# CY8C5888LTI_LP097 register map
File version: 0.1
Registers are 8-bit, read-write, no defined reset value unless marked. A register's access mark holds for its fields unless they carry their own. Offsets are from the block's base; [hi:lo] are bit positions; {n}, {i} and the like mark numbered series; 'fields as' and 'values as' point back to an identical list.

## ADC_DelSig_1
Base 0x00000000
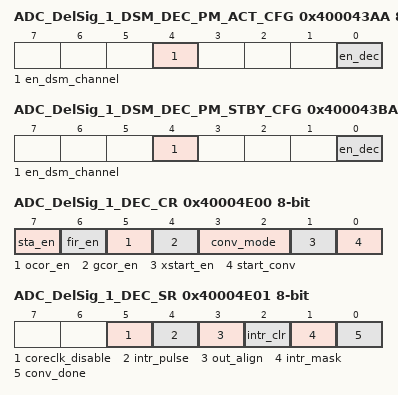
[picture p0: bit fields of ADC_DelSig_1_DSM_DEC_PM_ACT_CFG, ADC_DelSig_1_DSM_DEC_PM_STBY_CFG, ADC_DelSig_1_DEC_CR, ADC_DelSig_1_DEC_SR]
0x400043AA ADC_DelSig_1_DSM_DEC_PM_ACT_CFG — Decimator Active mode Power Register
  [4] en_dsm_channel — Enable delta-sigma modulator ADC channel. Note: set the appropriate enables in the analog interface prior to setting this global enable for the channel.
    0=Disable_DSM_Channel (Disable power to DSM channel.); 1=Enable_DSM_Channel (Enable power to DSM channel.)
  [0] en_dec — Enable decimator(s). Populated subsystems are counted from the LSB.
    0=DIS_DEC (Disable power to Decimator.); 1=EN_DEC (Enable power to Decimator.)
0x400043BA ADC_DelSig_1_DSM_DEC_PM_STBY_CFG — Decimator Alternate Active mode Power Register
  [4] en_dsm_channel — Enable delta-sigma modulator ADC channel. Note: set the appropriate enables in the analog interface prior to setting this global enable for the channel.
    0=Disable_DSM_Channel (Disable power to DSM channel.); 1=Enable_DSM_Channel (Enable power to DSM channel during Standby power mode.)
  [0] en_dec — Enable decimator(s). Populated subsystems are counted from the LSB.
    0=DIS_DEC (Disable power to Decimator.); 1=EN_DEC (Enable power to Decimator during Standby power mode.)
0x40004E00 ADC_DelSig_1_DEC_CR — Decimator Control Register
  [7] sta_en — Controls saturation logic in the Post Processing filter. When enabled, the resulting outputs of the Post Processing filter are held to the most positive or negative values, rather then wrapping around. Conversion results are unpredictable if this bit is changed while the Post Processing filter is running. This bit is ignored if FIR_EN, OCOR_EN and GCOR_EN are all 0.
    0=SAT_DIS (No saturation control.); 1=SAT_EN (Saturation Control Enabled.)
  [6] fir_en — Controls whether or not Post Processing filter implements a FIR filter. If this bit is set it enables the Post Processing filter. Conversion results are unpredictable if this bit is changed while the filter is running. The decimation period of this filter is controlled by the DR2 bits in register DR2 and DR2H.
    0=FIR_DIS (FIR filter function Disabled.); 1=FIR_EN (FIR filter function is on.)
  [5] ocor_en — This bit controls the offset correction feature of the Post Processing filter. If this bit is set it enables the Post Processing filter. The offset value is programmed in the OCOR bits of registers OCOR, OCORM and OCORH. Conversion results are unpredictable if this bit is changed while the filter is running.
    0=OCOR_DIS (No offset correction.); 1=OCOR_EN (Offset correction enabled.)
  [4] gcor_en — This bit controls the gain correction feature of the Post Processing filter. If this bit is set it enables the Post Processing filter. The gain coefficient is programmed in the GCOR bits of registers GCOR and GCORH. Which bits in this 16-bit field that are valid is set in GVAL. Conversion results are unpredictable if this bit is changed while the filter is running. When this feature is enabled, the DR1 register field must be set to a value higher than 32 (worst case) for proper operation.
    0=GCOR_DIS (Default: no gain correction.); 1=GCOR_EN (Gain correction enabled.)
  [3:2] conv_mode — The value in these two bits controls the sampling mode the Decimator runs in.
    0=SINGLE_SAMPLE (Single Sample Mode.); 1=FAST_FILTER (Fast Filter Mode.); 2=CONTINUOUS (Continuous Mode.); 3=FAST_FIR
  [1] xstart_en — Controls whether DSI signal ext_start is active. If XSTART_EN is high, it allows the ext_start input to start a conversion just as START_CONV does. Regardless of the state of this bit, writing to START_CONV will start a conversion.
    0=XSTART_DIS (Default: DSI signal ext_start is disabled.); 1=XSTART_EN (Enable the DSI input signal ext_start to start a conversion.)
  [0] start_conv — A write of 1 to this bit starts a conversion (regardless of the state of XSTART_EN) according to the CONV_MODE set in bits 2, 3. If read, a 1 indicates the filter is running when not in Single Sample mode. If a 0 is read the block is in the standby state when not in Single Sample mode. When in Single Sample more this bit is cleared shortly after it is written and does not reflect the running state of the Decimator.
    0=DEC_STOP (Kill current conversion (if running) and enter Standby state (SW reset).); 1=DEC_START (Initiate a conversion.)
0x40004E01 ADC_DelSig_1_DEC_SR — Decimator Status Register
  [5] coreclk_disable — This bit when set high disables (gates off) the clock to the entire core of the block (adc_clk). This includes all FFs except those used for the AHB interface and CSRs. When disabled (set high) the AHB interface to the CSR is still fully functional. This bit is ANDed with the primary input signal cic_clk_en to control the clock gate. cic_clk_en must be high and CoreCLK_Disable must be low for the clock to run.
    0=CORECLK_DISABLE_LOW (Core Clock is Enabled.); 1=CORECLK_DISABLE_HIGH (Core Clock is Disabled.)
  [4] intr_pulse — This read/write bit selects if cic_intr is pulse or level sensed. If level, a sample completion sets cic_intr high where it remains until bit 2 is written, a soft-reset if performed or if OUTSAMP/M/H is read. If pulse, a single cycle (pclk) strobe is generated on cic_intr to be used as an edge sensed interrupt or a DMAREQ. Regardless of which is selected, the interrupt output is still subject to masking by bit 1.
    0=INTR_LEVEL (Selects a level interrupt on cic_intr.); 1=INTR_PULSE (Selects a pulse interrupt on cic_intr.)
  [3] out_align — This bit when set high causes a read of OUTSAMP to produce the contents of OUTSAMPM and OUTSAMPM to produce the contents of OUTSAMPH. Effectively, this is an 8-bit right shift of the result. Note that the setting of this bit does not alter the content of the OUTSAMP registers. Setting this bit simply realigns the byte lanes when the register is read. If this bit is set low, the OUTSAMP registers are read normally.
    0=OUT_ALIGN_LOW (No affect on SAMP Registers.); 1=OUT_ALIGN_HIGH (Shifts SAMP registers right by 8-bits.)
  [2] intr_clr wo — INTR_CLR is a write-only bit that clears bit0 and cic_intr. A read always produces a 0.
    0=INTR_NOP (No affect.); 1=INTR_CLEAR (Clears CONV_DONE and the interrupt on cic_intr (if enabled).)
  [1] intr_mask — INTR_MASK is a RD/WR bit that controls the generation of the conversion completion interrupt. A read produces that last value written to this bit. This bit functions as a mask regardless of the value of bit 4 (INTR PULSE).
    0=INTR_ENABLED (Allows CONV_DONE to generate an interrupt.); 1=INTR_MASKED (Masks the interrupt generation on cic_intr.)
  [0] conv_done ro — CONV_DONE is a read-only bit indicating that the most recently started conversion has completed if it has been cleared since the last sample read. This same bit is the interrupt signal cic_intr when bit 4 is low, if not masked by bit 1. This bit is intended to provide a polling mechanism should this be preferred to receiving interrupts. It is cleared by writing a 1 to bit 2, a soft-reset or a read of register OUTSAMP, OUTSAMPM or OUTSAMPH (regardless of Coherency settings).
    0=CONV_NOTCOMP (Most recently started conversion completed.); 1=CONV_COMP (Conversion not completed since last clear.)
0x40004E02 ADC_DelSig_1_DEC_SHIFT1 — Decimator Shift Register
  [4:0] shift1 — Value for left shift amount of modulator input data. 0 = no shift, 1 = left shift by 1 bit, .... up to the max supported 31.
0x40004E03 ADC_DelSig_1_DEC_SHIFT2 — Decimator Shift Register
  [3:0] shift2 — Value for the amount of right shift for the output of the CIC filter prior to entering the Post Processor. Functional values range from 0 to 15, 0 = no shift.
0x40004E04 ADC_DelSig_1_DEC_DR2 — Decimator Decimation Rate (2) Register
  [7:0] dr2_low — FIR Filter decimation ratio bits [7:0] (of [9:0]).
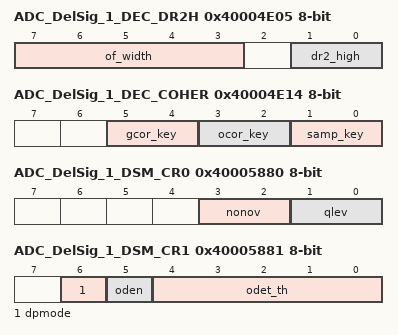
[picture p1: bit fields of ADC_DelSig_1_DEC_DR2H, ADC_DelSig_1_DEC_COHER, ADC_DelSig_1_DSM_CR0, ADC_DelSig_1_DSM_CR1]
0x40004E05 ADC_DelSig_1_DEC_DR2H — Decimator Decimation Rate and Overflow Correction Register
  [7:3] of_width — Occupying the top 5 bits of this register is the Overflow Correction Bit-Width field (it is unrelated to the DR2). This field both enables and sets the bit width of the Overflow Correction logic in the CIC core.
  [1:0] dr2_high — FIR Filter decimation ratio bits [9:8] (of [9:0]). See description in DR2 register.
0x40004E06 ADC_DelSig_1_DEC_DR1 — Decimator Decimation Rate (1) Register
  [7:0] dr1 — CIC Filter decimation rate.
0x40004E08 ADC_DelSig_1_DEC_OCOR — Decimator Offset Correction Coefficient (Low Byte) Register
  [7:0] ocor_low — Offset correction coefficient bits [7:0] (of [23:0]).
0x40004E09 ADC_DelSig_1_DEC_OCORM — Decimator Offset Correction Coefficient (Middle Byte) Register
  [7:0] ocor_mid — Offset correction coefficient bits [15:8] (of [23:0]).
0x40004E0A ADC_DelSig_1_DEC_OCORH — Decimator Offset Correction Coefficient (High Byte) Register
  [7:0] ocor_high — Offset correction coefficient bits [23:16] (of [23:0]).
0x40004E0C ADC_DelSig_1_DEC_GCOR — Decimator Gain Correction Coefficient (Low Byte) Register
  [7:0] gcor_low — Gain correction coefficient bits [7:0] (of [15:0]).
0x40004E0D ADC_DelSig_1_DEC_GCORH — Decimator Gain Correction Coefficient (High Byte) Register
  [7:0] gcor_high — Gain correction coefficient bits [15:8] (of [15:0]).
0x40004E0E ADC_DelSig_1_DEC_GVAL — Decimator Gain Correction Size Register
  [3:0] gval — Number of valid bits minus one in Gain Coefficient registers GCORH and GCOR.
0x40004E10 ADC_DelSig_1_DEC_OUTSAMP — Decimator Output Data Sample (Low Byte) Register
  [7:0] samp_low ro — Low order byte of the filter conversion result, bits [7:0] (of [23:0]) --- Or if the out_align bit is set it contains bits [15:8] (of [23:0]).
0x40004E11 ADC_DelSig_1_DEC_OUTSAMPM — Decimator Output Data Sample (Middle Byte) Register
  [7:0] samp_mid ro — Middle order byte of the filter conversion result, bits [15:8] (of [23:0]) --- Or if the out_align bit is set it contains bits [23:16] (of [23:0]).
0x40004E12 ADC_DelSig_1_DEC_OUTSAMPH — Decimator Output Data Sample (High Byte) Register
  [7:0] samp_high ro — High order byte of the filter conversion result, bits [23:16] (of [23:0]).
0x40004E14 ADC_DelSig_1_DEC_COHER — Decimator Coherency Register
  [5:4] gcor_key — Sets the Key Coherency Byte of the GCOR/GCORH/GVAL field.
    0=GCOR_KEY_OFF (Gain Coefficient Coherency checking off.); 1=GCOR_KEY_LOW (Key Byte is low byte (GCOR).); 2=GCOR_KEY_MID (Key Byte is middle byte (GCORH).); 3=GCOR_KEY_HIGH (Key Byte is high byte (GVAL).)
  [3:2] ocor_key — Sets the Key Coherency Byte of the OCOR/OCORM/OCORH field.
    0=OCOR_KEY_OFF (Offset Coefficient Coherency checking off.); 1=OCOR_KEY_LOW (Key Byte is low byte (OCOR).); 2=OCOR_KEY_MID (Key Byte is middle byte (OCORM).); 3=OCOR_KEY_HIGH (Key Byte is high byte (OCORH).)
  [1:0] samp_key — Sets the Key Coherency Byte of the OUTSAMP/OUTSAMPM/OUTSAMPH field.
    0=SAMP_KEY_OFF (Output Sample Coherency checking off.); 1=SAMP_KEY_LOW (Key Byte is low byte (OUTSAMP).); 2=SAMP_KEY_MID (Key Byte is middle byte (OUTSAMPM).); 3=SAMP_KEY_HIGH (Key Byte is high byte (OUTSAMPH).)
0x40005880 ADC_DelSig_1_DSM_CR0 — Delta Sigma Modulator Control Register 0
  [3:2] nonov — Non overlap delay of clock phases.
    0=NONOV_LOW (low (1.57ns, typ).); 1=NONOV_MEDIUM (medium (3.54ns, typ).); 2=NONOV_HIGH (high (6.47ns, typ).); 3=NONOV_VERYHIGH (very high (9.91ns, typ).)
  [1:0] qlev — Quantization Level choice for modulator.
    0=2 level quantization; 1=3 level quantization; 2=9 level quantization; 3=QLEV_9_ALSO (9 level quantization.)
0x40005881 ADC_DelSig_1_DSM_CR1 — Delta Sigma Modulator Control Register 1
  [6] dpmode — Datapath mode.
    0=DPMODE_NORMAL (normal.); 1=DPMODE_LOWOFFSET (low offset.)
  [5] oden — Overload detect scheme enable.
  [4:0] odet_th — Overload detection threshold. If the number of continuous 1s or 0s coming out of quantizer exceeds this number overload detection flag is set.
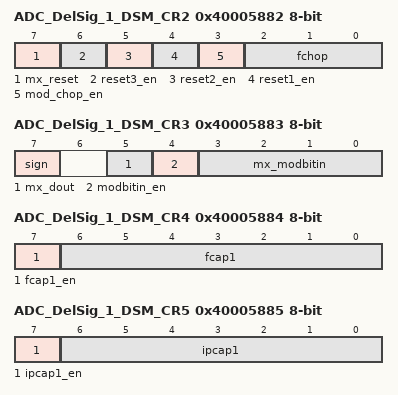
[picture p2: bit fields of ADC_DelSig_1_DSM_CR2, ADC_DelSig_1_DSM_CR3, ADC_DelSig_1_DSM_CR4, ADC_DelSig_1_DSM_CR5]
0x40005882 ADC_DelSig_1_DSM_CR2 — Delta Sigma Modulator Control Register 2
  [7] mx_reset — select DSM reset source.
    0=MXSELRESET_0 (Select Decimator for reset source.); 1=MXSELRESET_1 (Select UDB for reset source.)
  [6] reset3_en — allow third stage integrating capacitance to be reset.
    0=RESET3_EN_DISABLE (third stage integrating capacitance cannot be reset (use only for debug purposes).); 1=RESET3_EN_ENABLE (third stage integrating capacitance can be reset.)
  [5] reset2_en — allow second stage integrating capacitance to be reset.
    0=RESET2_EN_DISABLE (second stage integrating capacitance cannot be reset (use when in overload, to allow for second order operation, assuming the reset1_en bit is also cleared.); 1=RESET2_EN_ENABLE (second stage integrating capacitance can be reset.)
  [4] reset1_en — Allow first stage integrating capacitance to be reset.
    0=RESET1_EN_DISABLE (First stage integrating capacitance cannot be reset (use when in overload, to allow for first order operation).); 1=RESET1_EN_ENABLE (First stage integrating capacitance can be reset.)
  [3] mod_chop_en — Enable Modulator Chopping.
    0=MOD_CHOP_DIS (Disable modulator chopping.); 1=MOD_CHOP_EN (Enable modulator chopping.)
  [2:0] fchop — Chopping Frequency Selection. The Fclock is samply frequency clock.
    0=FCHOP_DIV2 (Fclock/2.); 1=FCHOP_DIV4 (Fclock/4.); 2=FCHOP_DIV8 (Fclock/8.); 3=FCHOP_DIV16 (Fclock/16.); 4=FCHOP_DIV32 (Fclock/32.); 5=FCHOP_DIV64 (Fclock/64.); 6=FCHOP_DIV128 (Fclock/128.); 7=FCHOP_DIV256 (Fclock/256.)
0x40005883 ADC_DelSig_1_DSM_CR3 — Delta Sigma Modulator Control Register 3
  [7] sign — Invert sign of input.
    0=SIGN_NONINVERT (keep original polarity for the input.); 1=SIGN_INVERT (Invert sign of input (use when trying to chop once and then average the offset value out).)
  [5] mx_dout — Select DSM dout routed to UDB.
    0=MX_DOUT_8BIT (Select reg OUT0=dout[7:0] (synced; w/o post processing).); 1=MX_DOUT_2SCOMP (Select reg OUT1={2'b0,ovdcause,ovdflag,dout2scomp} (synced; overload cause, overload flag, dout 2s complement.)
  [4] modbitin_en — modbitin enable.
    0=MODBITIN_EN_DISABLE (Do not allow modbit input to be mixed with modulator input.); 1=MODBITIN_EN_ENABLE (Allow modbit input to be mixed with modulator input.)
  [3:0] mx_modbitin — Select modbitin input.
    {v}=MX_MODBITIN_LUT{v} (lut{v}_out.) (v=0..3); {v}=MX_MODBITIN_LUT{v} (lut{v}_out (doesn't exist on Leopard, tied to 0).) (v=4..7); 8=MX_MODBITIN_UDB (UDB.); 9=MX_MODBITIN_CONST1 (constant 1.); 10=MX_MODBITIN_CONST0 (constant 0.); {v}=MX_MODBITIN_{0x0+v}_RSVD (Reserved.) (v=11..15)
0x40005884 ADC_DelSig_1_DSM_CR4 — Delta Sigma Modulator Control Register 4
  [7] fcap1_en — Enable/Disable Capacitance path meant for DFT (Design for Testability) of the first integrator's integrating capacitance path.
    0=FCAP1_EN_DISABLE (Disable the DFT 100fF capacitance path.); 1=FCAP1_EN_ENABLE (Enable the DFT 100fF capacitance path.)
  [6:0] fcap1 — binary weighted first stage integrating capacitance.
    0=FCAP1_MIN (0 fF.); 127=FCHOP_MAX (Max Value = 12.7 pF.); 1=FCAP1_BIT0 (fcap[0] set -> +100 fF.); 2=FCAP1_BIT1 (fcap[1] set -> +200 fF.); 4=FCAP1_BIT2 (fcap[2] set -> +400 fF.); 8=FCAP1_BIT3 (fcap[3] set -> +800 fF.); 16=FCAP1_BIT4 (fcap[4] set -> +1600 fF.); 32=FCAP1_BIT5 (fcap[5] set -> +3200 fF.); 64=FCAP1_BIT6 (fcap[6] set -> +6400 fF.)
0x40005885 ADC_DelSig_1_DSM_CR5 — Delta Sigma Modulator Control Register 5
  [7] ipcap1_en — Enable/Disable Capacitance path meant for DFT (Design for Testability) of the first integrator's input sampling path.
    0=IPCAP1_EN_DISABLE (Disable the DFT 100fF capacitance path.); 1=IPCAP1_EN_ENABLE (Enable the DFT 100fF capacitance path.)
  [6:0] ipcap1 — Binary weighted first stage integrating capacitance.
    0=IPCAP1_MIN (0 fF.); 127=IPCHOP_MAX (Max Value = 12.7 pF.); 1=IPCAP1_BIT0 (ipcap[0] set -> +100 fF.); 2=IPCAP1_BIT1 (ipcap[1] set -> +200 fF.); 4=IPCAP1_BIT2 (ipcap[2] set -> +400 fF.); 8=IPCAP1_BIT3 (ipcap[3] set -> +800 fF.); 16=IPCAP1_BIT4 (ipcap[4] set -> +1600 fF.); 32=IPCAP1_BIT5 (ipcap[5] set -> +3200 fF.); 64=IPCAP1_BIT6 (ipcap[6] set -> +6400 fF.)
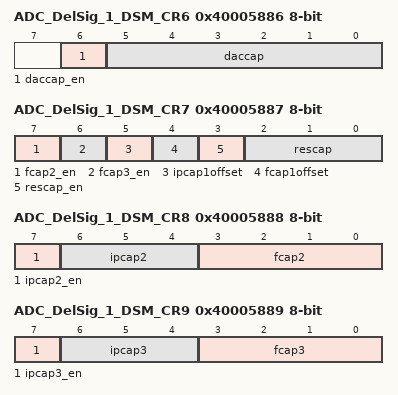
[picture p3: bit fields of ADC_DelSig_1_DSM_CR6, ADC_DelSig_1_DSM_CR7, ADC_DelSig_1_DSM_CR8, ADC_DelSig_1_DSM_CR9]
0x40005886 ADC_DelSig_1_DSM_CR6 — Delta Sigma Modulator Control Register 6
  [6] daccap_en — Enable/Disable Capacitance path meant for DFT (Design for Testability) of the DAC Reference sampling path.
    0=DACCAP_EN_DISABLE (Disable the DFT 12fF capacitance path.); 1=DACCAP_EN_ENABLE (Enable the DFT 12fF capacitance path.)
  [5:0] daccap — Binary weighted first stage DAC capacitance.
    1=DACCAP_BIT0 (daccap[0] set -> add 12*8= +96 fF.); 2=DACCAP_BIT1 (daccap[1] set -> add 24*8= +192 fF.); 4=DACCAP_BIT2 (daccap[2] set -> add 50*8= +400 fF.); 8=DACCAP_BIT3 (daccap[3] set -> add 100*8= +800 fF.); 16=DACCAP_BIT4 (daccap[4] set -> add 200*8= +1600 fF.); 32=DACCAP_BIT5 (daccap[5] set -> add 400*8= +3200 fF.)
0x40005887 ADC_DelSig_1_DSM_CR7 — Delta Sigma Modulator Control Register 7
  [7] fcap2_en — Enable/Disable additional 50fF capacitance path in the second integrators integrating capacitance path.
    0=FCAP2_EN_DISABLE (Disable the additional 50fF capacitance path.); 1=FCAP2_EN_ENABLE (Enable the additional 50fF capacitance path.)
  [6] fcap3_en — Enable/Disable additional capacitance path in the third integrator's integrating capacitance path.
    0=FCAP3_EN_DISABLE (Disable the additional 100fF capacitance path.); 1=FCAP3_EN_ENABLE (Enable the additional 100fF capacitance path.)
  [5] ipcap1offset — Offset capacitance for the input sampling capacitance in the first stage integrator.
    0=Don't add offset capacitance; 1=Add offset capacitance of 4.8 pF
  [4] fcap1offset — Offset Capacitance for the integrating capacitance in the first stage integrator.
    0=Don't add offset capacitance; 1=Add offset capacitance of 3.4 pF
  [3] rescap_en — Reserved. The resonator loop feature has been disabled in the design; programming these bits does not produce any change in the ADC outcome.
  [2:0] rescap — Reserved. The resonator loop feature has been disabled in the design; programming these bits does not produce any change in the ADC outcome.
0x40005888 ADC_DelSig_1_DSM_CR8 — Delta Sigma Modulator Control Register 8
  [7] ipcap2_en — Enable/Disable additional 50fF capacitance path in the second integrator's input sampling path.
    0=IPCAP2_EN_DISABLE (Disable the additional 50fF capacitance path.); 1=IPCAP2_EN_ENABLE (Enable the additional 50fF capacitance path.)
  [6:4] ipcap2 — The second integrator's input sampling capacitance (0-350fF, 50fF step).
    0=IPCAP2_0FEMPTO (0fF.); 1=IPCAP2_50FEMPTO (50fF.); 2=IPCAP2_100FEMPTO (100fF.); 3=IPCAP2_150FEMPTO (150fF.); 4=IPCAP2_200FEMPTO (200fF.); 5=IPCAP2_250FEMPTO (250fF.); 6=IPCAP2_300FEMPTO (300fF.); 7=IPCAP2_350FEMPTO (350fF.)
  [3:0] fcap2 — The second stage integrating capacitance (0-750fF, 50fF step).
    0=FCAP2_0FEMPTO (0fF.); 1=FCAP2_50FEMPTO (50fF.); 2=FCAP2_100FEMPTO (100fF.); 3=FCAP2_150FEMPTO (150fF.); 4=FCAP2_200FEMPTO (200fF.); 5=FCAP2_250FEMPTO (250fF.); 6=FCAP2_300FEMPTO (300fF.); 7=FCAP2_350FEMPTO (350fF.); 8=FCAP2_400FEMPTO (400fF.); 9=FCAP2_450FEMPTO (450fF.); 10=FCAP2_500FEMPTO (500fF.); 11=FCAP2_550FEMPTO (550fF.); 12=FCAP2_600FEMPTO (600fF.); 13=FCAP2_650FEMPTO (650fF.); 14=FCAP2_700FEMPTO (700fF.); 15=FCAP2_750FEMPTO (750fF.)
0x40005889 ADC_DelSig_1_DSM_CR9 — Delta Sigma Modulator Control Register 9
  [7] ipcap3_en — Enable/Disable additional 50fF capacitance path in the second integrator's input sampling path.
    0=IPCAP3_EN_DISABLE (Disable the additional 50fF capacitance path.); 1=IPCAP3_EN_ENABLE (Enable the additional 50fF capacitance path.)
  [6:4] ipcap3 — The third integrator's input sampling capacitance (0-350fF in 50fF step).
    0=IPCAP3_0FEMPTO (0fF.); 1=IPCAP3_50FEMPTO (50fF.); 2=IPCAP3_100FEMPTO (100fF.); 3=IPCAP3_150FEMPTO (150fF.); 4=IPCAP3_200FEMPTO (200fF.); 5=IPCAP3_250FEMPTO (250fF.); 6=IPCAP3_300FEMPTO (300fF.); 7=IPCAP3_350FEMPTO (350fF.)
  [3:0] fcap3 — The third stage integrating capacitance (0-1500fF, 100fF step).
    0=FCAP3_0FEMPTO (0fF.); 1=FCAP3_100FEMPTO (100fF.); 2=FCAP3_200FEMPTO (200fF.); 3=FCAP3_300FEMPTO (300fF.); 4=FCAP3_400FEMPTO (400fF.); 5=FCAP3_500FEMPTO (500fF.); 6=FCAP3_600FEMPTO (600fF.); 7=FCAP3_700FEMPTO (700fF.); 8=FCAP3_800FEMPTO (800fF.); 9=FCAP3_900FEMPTO (900fF.); 10=FCAP3_1000FEMPTO (1000fF.); 11=FCAP3_1100FEMPTO (1100fF.); 12=FCAP3_1200FEMPTO (1200fF.); 13=FCAP3_1300FEMPTO (1300fF.); 14=FCAP3_1400FEMPTO (1400fF.); 15=FCAP3_1500FEMPTO (1500fF.)
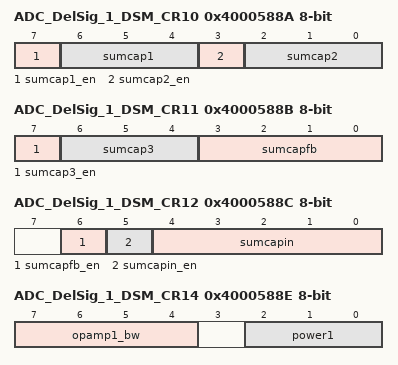
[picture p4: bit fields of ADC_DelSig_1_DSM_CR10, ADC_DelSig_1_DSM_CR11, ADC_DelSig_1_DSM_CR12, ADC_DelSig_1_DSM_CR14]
0x4000588A ADC_DelSig_1_DSM_CR10 — Delta Sigma Modulator Control Register 10
  [7] sumcap1_en — Enabling/Disabling the the additional 50fF capacitance path that lies between first integrator output and summer input (feed-forward) path.
    0=SUMCAP1_EN_DISABLE (Disable the additional 50fF capacitance path.); 1=SUMCAP1_EN_ENABLE (Enable the additional 50fF capacitance path.)
  [6:4] sumcap1 — The summer capacitance that lies on the feed-forward path from the first integrator output (0fF to 350fF in 50fF step).
    0=SUMCAP1_0FEMPTO (0fF.); 1=SUMCAP1_50FEMPTO (50fF.); 2=SUMCAP1_100FEMPTO (100fF.); 3=SUMCAP1_150FEMPTO (150fF.); 4=SUMCAP1_200FEMPTO (200fF.); 5=SUMCAP1_250FEMPTO (250fF.); 6=SUMCAP1_300FEMPTO (300fF.); 7=SUMCAP1_350FEMPTO (350fF.)
  [3] sumcap2_en — Enabling/Disabling the additional 50fF capacitance path that lies between the second integrator output and summer input (feed-forward) path.
    0=SUMCAP2_EN_DISABLE (Disable the additional 50fF capacitance path.); 1=SUMCAP2_EN_ENABLE (Enable the additional 50fF capacitance path.)
  [2:0] sumcap2 — The summer capacitance that lies on the feed-forward path from the second integrator output (0fF to 350fF in 50fF step.
    0=SUMCAP2_0FEMPTO (0fF.); 1=SUMCAP2_50FEMPTO (50fF.); 2=SUMCAP2_100FEMPTO (100fF.); 3=SUMCAP2_150FEMPTO (150fF.); 4=SUMCAP2_200FEMPTO (200fF.); 5=SUMCAP2_250FEMPTO (250fF.); 6=SUMCAP2_300FEMPTO (300fF.); 7=SUMCAP2_350FEMPTO (350fF.)
0x4000588B ADC_DelSig_1_DSM_CR11 — Delta Sigma Modulator Control Register 11
  [7] sumcap3_en — Enabling/Disabling the additional 50fF path that lies between the third integrator output and summer input (feed-forward) path.
    0=SUMCAP3_EN_DISABLE (Disable the additional 50fF capacitance path.); 1=SUMCAP3_EN_ENABLE (Enable the additional 50fF capacitance path.)
  [6:4] sumcap3 — The summer capacitance that lies on the feed-forward path from the third integrator output (0fF to 350fF in 50fF step.
    0=SUMCAP3_0FEMPTO (0fF.); 1=SUMCAP3_50FEMPTO (50fF.); 2=SUMCAP3_100FEMPTO (100fF.); 3=SUMCAP3_150FEMPTO (150fF.); 4=SUMCAP3_200FEMPTO (200fF.); 5=SUMCAP3_250FEMPTO (250fF.); 6=SUMCAP3_300FEMPTO (300fF.); 7=SUMCAP3_350FEMPTO (350fF.)
  [3:0] sumcapfb — The summer feedback capacitance (0fF to 750F in 50fF step).
    0=SUMCAPFB_0FEMPTO (0fF.); 1=SUMCAPFB_50FEMPTO (50fF.); 2=SUMCAPFB_100FEMPTO (100fF.); 3=SUMCAPFB_150FEMPTO (150fF.); 4=SUMCAPFB_200FEMPTO (200fF.); 5=SUMCAPFB_250FEMPTO (250fF.); 6=SUMCAPFB_300FEMPTO (300fF.); 7=SUMCAPFB_350FEMPTO (350fF.); 8=SUMCAPFB_400FEMPTO (400fF.); 9=SUMCAPFB_450FEMPTO (450fF.); 10=SUMCAPFB_500FEMPTO (500fF.); 11=SUMCAPFB_550FEMPTO (550fF.); 12=SUMCAPFB_600FEMPTO (600fF.); 13=SUMCAPFB_650FEMPTO (650fF.); 14=SUMCAPFB_700FEMPTO (700fF.); 15=SUMCAPFB_750FEMPTO (750fF.)
0x4000588C ADC_DelSig_1_DSM_CR12 — Delta Sigma Modulator Control Register 12
  [6] sumcapfb_en — Enabling/Disabling the DFT path that lies on the feedback path of the active summer.
    0=SUMCAPFB_EN_DISABLE (Disable the DFT 50fF capacitance path.); 1=SUMCAPFB_EN_ENABLE (Enable the DFT 50fF capacitance path.)
  [5] sumcapin_en — Enabling/Disabling the DFT path that lies between input of the sigma delta modulator and the summer input..
    0=SUMCAPIN_EN_DISABLE (Disable the DFT 50fF capacitance path.); 1=SUMCAPIN_EN_ENABLE (Enable the DFT 50fF capacitance path.)
  [4:0] sumcapin — The summer capacitance that lies on the path where the input signal is summed (50fF to 1.6pF in 50fF step).
    0=SUMCAPIN_0FEMPTO (0fF.); 1=SUMCAPIN_50FEMPTO (50fF.); 2=SUMCAPIN_100FEMPTO (100fF.); 3=SUMCAPIN_150FEMPTO (150fF.); 4=SUMCAPIN_200FEMPTO (200fF.); 5=SUMCAPIN_250FEMPTO (250fF.); 6=SUMCAPIN_300FEMPTO (300fF.); 7=SUMCAPIN_350FEMPTO (350fF.); 8=SUMCAPIN_400FEMPTO (400fF.); 9=SUMCAPIN_450FEMPTO (450fF.); 10=SUMCAPIN_500FEMPTO (500fF.); 11=SUMCAPIN_550FEMPTO (550fF.); 12=SUMCAPIN_600FEMPTO (600fF.); 13=SUMCAPIN_650FEMPTO (650fF.); 14=SUMCAPIN_700FEMPTO (700fF.); 15=SUMCAPIN_750FEMPTO (750fF.); 16=SUMCAPIN_800FEMPTO (800fF.); 17=SUMCAPIN_850FEMPTO (850fF.); 18=SUMCAPIN_900FEMPTO (900fF.); 19=SUMCAPIN_950FEMPTO (950fF.); 20=SUMCAPIN_1000FEMPTO (1000fF.); 21=SUMCAPIN_1050FEMPTO (1050fF.); 22=SUMCAPIN_1100FEMPTO (1100fF.); 23=SUMCAPIN_1150FEMPTO (1150fF.); 24=SUMCAPIN_1200FEMPTO (1200fF.); 25=SUMCAPIN_1250FEMPTO (1250fF.); 26=SUMCAPIN_1300FEMPTO (1300fF.); 27=SUMCAPIN_1350FEMPTO (1350fF.); 28=SUMCAPIN_1400FEMPTO (1400fF.); 29=SUMCAPIN_1450FEMPTO (1450fF.); 30=SUMCAPIN_1500FEMPTO (1500fF.); 31=SUMCAPIN_1550FEMPTO (1550fF.)
0x4000588D ADC_DelSig_1_DSM_CR13 — Delta Sigma Modulator Control Register 13
0x4000588E ADC_DelSig_1_DSM_CR14 — Delta Sigma Modulator Control Register 14
  [7:4] opamp1_bw — First Stage Opamp Bandwidth Control (Risk Mitigation not for User control). Table gives value for Modulator input bw[3:0].
    0=(default); 1=(used with 1.5X power); 3=(used with 2X power); 7=(used with 2.5X power); 8=(higher BW, 1.25X power); 9=(lower noise)
  [2:0] power1 — First Stage Opamp Power level control.
    0=Low (44uA); 1=Medium (123uA); 2=High (492uA); 3=1.5X (750uA); 4=2X (1mA); 5=C/2 @ 3MSPS (277uA); 6=C/4 @ 3MSPS (185uA); 7=2.5X (1.5mA)
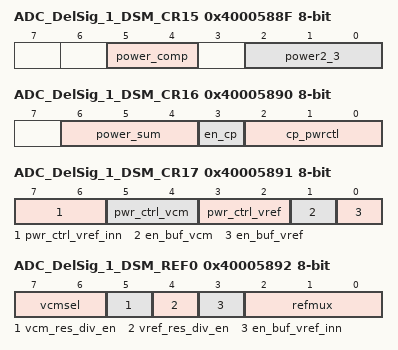
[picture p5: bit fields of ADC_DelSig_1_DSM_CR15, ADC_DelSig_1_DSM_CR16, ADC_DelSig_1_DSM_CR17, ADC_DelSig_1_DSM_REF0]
0x4000588F ADC_DelSig_1_DSM_CR15 — Delta Sigma Modulator Control Register 15
  [5:4] power_comp — The power control for the quantizer block.
    0=POWER_COMP_VERYLOW (very low (2.2uA)); 1=POWER_COMP_NORMAL (Normal (8.6uA)); 2=POWER_COMP_6MHZ (6MHz (17uA)); 3=POWER_COMP_12MHZ (12MHz (35uA))
  [2:0] power2_3 — The power control for the second and third integrator stages.
    0=POWER2_3_LOW (LOW (4uA)); 1=POWER2_3_MEDIUM (MEDIUM (17uA)); 2=POWER2_3_HIGH (HIGH (68uA)); 3=POWER2_3_1P5X (1.5X (100uA)); 4=POWER2_3_2X (2X (135uA)); 5=POWER2_3_HIGH_5 (HIGH (68uA)); 6=POWER2_3_HIGH_6 (HIGH (68uA)); 7=POWER2_3_HIGH_7 (HIGH (68uA))
0x40005890 ADC_DelSig_1_DSM_CR16 — Delta Sigma Modulator Control Register 16
  [6:4] power_sum — The power control for the summer block.
    0=POWER_SUM_LOW (LOW (4uA)); 1=POWER_SUM_MEDIUM (MEDIUM (17uA)); 2=POWER_SUM_HIGH (HIGH (68uA)); 3=POWER_SUM_1P5X (1.5X (100uA)); 4=POWER_SUM_2X (2X (135uA)); 5=POWER_SUM_HIGH_5 (HIGH (68uA)); 6=POWER_SUM_HIGH_6 (HIGH (68uA)); 7=POWER_SUM_HIGH_7 (HIGH (68uA))
  [3] en_cp — Enable charge pump.
    0=CP_DISABLE (Disable charge pump); 1=CP_ENABLE (Enable charge pump)
  [2:0] cp_pwrctl — Charge Pump Power Control Modes.
    0=CP_PWRCTL_TURBO (Charge pump operating in Turbo Power (560uA) mode); 1=CP_PWRCTL_2X (Charge pump operating in 6MHz (300uA) mode); 2=CP_PWRCTL_HIGH (Charge pump operating in High power (170uA) mode); 3=CP_PWRCTL_MEDIUM (Charge pump operating in Medium power (70uA) mode); 4=CP_PWRCTL_LOW (Charge pump operating in Low Power (30uA) mode)
0x40005891 ADC_DelSig_1_DSM_CR17 — Delta Sigma Modulator Control Register 17
  [7:6] pwr_ctrl_vref_inn — Power control modes for REFBUF1 (the reference buffer that connects ADC reference to the negative input MUX of the channel).
    0=PWR_CTRL_VREF_INN_LOW (VREF Buffer (Input mux path) is operating in Low Power (26uA) mode); 1=PWR_CTRL_VREF_INN_MEDIUM (VREF Buffer (Input mux path) is operating in Medium Power (32uA) mode); 2=PWR_CTRL_VREF_INN_HIGH (VREF Buffer (Input mux path) is operating in High Power (118uA) mode); 3=PWR_CTRL_VREF_INN_TURBO (VREF Buffer (Input mux path) is operating in Turbo Power (232uA) mode)
  [5:4] pwr_ctrl_vcm — Power Control for the Voltage Common Mode Buffer for the Sigma Delta ADC.
    0=VCM Buffer is operating in Low Power (18 uA) mode; 1=VCM Buffer is operating in Medium Power (28 uA) mode; 2=VCM Buffer is operating in High Power (55 uA) mode; 3=VCM Buffer is operating in Turbo Power (114 uA) mode
  [3:2] pwr_ctrl_vref — Power Control for the Voltage Reference Buffer for the Sigma Delta ADC.
    0=VREF Buffer is operating in Low Power (26 uA) mode; 1=VREF Buffer is operating in Medium Power (32 uA) mode; 2=VREF Buffer is operating in High Power (118 uA) mode; 3=VREF Buffer is operating in Turbo Power (232 uA) mode
  [1] en_buf_vcm — Enable/Disable control for ADC (Internal)Reference Buffer.
    0=The ADC Output common mode (VCM) voltage buffer is powered down; 1=The ADC Output common mode (VCM) voltage buffer is NOT powered down
  [0] en_buf_vref — Enable/Disable control for ADC (Internal)Reference Buffer.
    0=The Internal Reference Voltage Buffer is powered down; 1=The Internal Reference Voltage Buffer is NOT powered down
0x40005892 ADC_DelSig_1_DSM_REF0 — Delta Sigma Modulator Reference Register 0
  [7:6] vcmsel — Output common mode selection for modulator
    0=No selection is made for VCM; 1=0.8V from bandgap trim buffer is being selected as VCM (output common mode) for the DSM opamps; 0=0.7V from bandgap trim buffer is being selected as VCM (output common mode); 1=Vssd being selected as VCM (output common mode) for the DSM opamps
  [5] vcm_res_div_en — If enabled it allows the resistor divided value of (Vpwra/2) to a selectable voltage for the VCM Mux
    0=VCM_RES_DIV_DISABLE (VCM resistor divider disabled); 1=VCM_RES_DIV_ENABLE (VCM resistor divider enabled)
  [4] vref_res_div_en — If enabled it allows the resistor divided value of (Vda/4) to a selectable voltage for the RefMux
    0=VREF_RES_DIV_DISABLE (VREF resistor divider disabled); 1=VREF_RES_DIV_ENABLE (VREF resistor divider enabled)
  [3] en_buf_vref_inn — Enable/Disable control for ADC (internal) REFBUF1 Buffer; This buffers the ADC reference before being sent to INN Mux.
  [2:0] refmux — Mux control that allows for selecting one among the various available internal reference values
    0=No Selection made for VCM; 1=VDAC0 output is the reference for the DSM; 2=Vda/4 is selected as the reference for the DSM (Vda is the external voltage supply); 3=Vda/3 is selected as the reference for the DSM (Vda is the external voltage supply); 4=internal precision bandgap reference of 1.024 (typ) is selected as the DSM reference; 5=internal precision bandgap reference of 1.2V (typ) is selected as the DSM reference; 6=N/A; 7=N/A
0x40005893 ADC_DelSig_1_DSM_REF1 — Delta Sigma Modulator Reference Register 1
  [0] dac_gnd_sel — Selects DSM Reference DAC Capacitor Ground.
    0=DSM_DAC_GND_SEL_INT (select DSM internal vssa); 1=DSM_DAC_GND_SEL_EXT (select external ground (AGL6))
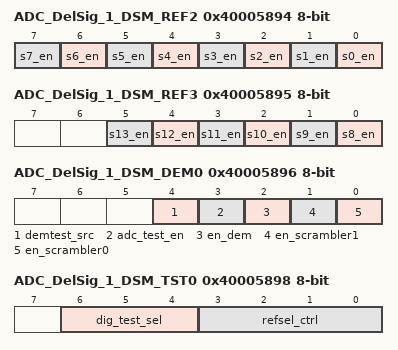
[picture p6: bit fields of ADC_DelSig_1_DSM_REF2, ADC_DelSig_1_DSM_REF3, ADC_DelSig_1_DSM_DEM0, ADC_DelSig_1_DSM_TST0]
0x40005894 ADC_DelSig_1_DSM_REF2 — Delta Sigma Modulator Reference Register 2
  [n] s{n}_en (n=0..7) — If Set, closes the S{n} switch in figure Sigma Delta Channel Analog Reference Selection in the DSM chapter; See sub-section Analog Reference Options for the Sigma Delta Channel.
0x40005895 ADC_DelSig_1_DSM_REF3 — Delta Sigma Modulator Reference Register 3
  [n-8] s{n}_en (n=8..13) — If Set, closes the S{n} switch in figure Sigma Delta Channel Analog Reference Selection in the DSM chapter; See sub-section Analog Reference Options for the Sigma Delta Channel.
0x40005896 ADC_DelSig_1_DSM_DEM0 — Delta Sigma Modulator Dynamic Element Matching Register 0
  [4] demtest_src — Select demtest source.
    0=DEMTEST_SRC_REG (ANAIF register source selected - DSM#_DEM1.demtest[7:0].); 1=DEMTEST_SRC_UDB (UDB array source selected - dsi_anaif_dft[7:0].)
  [3] adc_test_en — Enable/Disable All test modes in Sigma Delta Channel.
    0=Disable all test modes for the sigma delta channel; 1=Enable all test modes for the sigma delta channel
  [2] en_dem — Enable DEM.
    0=EN_DEM_DISABLE (Disable DEM); 1=EN_DEM_ENABLE (Enable DEM)
  [1] en_scrambler1 — Enable Scrambler 1.
    0=EN_SCRAMBLER1_DISABLE (Disable Scrambler 1); 1=EN_SCRAMBLER1_ENABLE (Enable Scrambler 1)
  [0] en_scrambler0 — Enable Scrambler 0.
    0=EN_SCRAMBLER0_DISABLE (Disable Scrambler 0); 1=EN_SCRAMBLER0_ENABLE (Enable Scrambler 0)
0x40005897 ADC_DelSig_1_DSM_DEM1 — Delta Sigma Modulator Dynamic Element Matching Register 1
  [7:0] demtest — Register control for the DAC unit elements inside the first integrator. This can be used when bit DSM.DEM0[3], adc_test_en, is set. If the adc_test_en is not set the the control logic inside the modulator determines how the DAC unit elements are controlled. This is meant for static testing purposes.
0x40005898 ADC_DelSig_1_DSM_TST0 — Delta Sigma Modulator Test Register 0
  [6:4] dig_test_sel — To test various digital outputs to digital muxes (for DFT).
    0=test_dig_out = vhi; 1=test_dig_out = hi; 2=test_dig_out = med; 3=test_dig_out = low; 4=test_dig_out = sign; 5=test_dig_out = reset_ov; 6=test_dig_out = TESTMODE and Phi1 (sampling clock phase); 7=test_dig_out = TESTMODE and fchclk (chopping clock)
  [3:0] refsel_ctrl — This is the 4-bit encoded value which selects one among the 15 important DFT observable points inside the DSM. 4'h0 (0000) through 4'ha (1010) selects between various tap points in the quantizer resistor ladder. 4'hb (1011) through 4'he (1110) selects special points inside the DSM.
    0=(9/32)*Vref; 1=(11/32)*Vref; 2=(12/32)*Vref; 3=(13/32)*Vref; 4=(15/32)*Vref; 5=(16/32)*Vref; 6=(17/32)*Vref; 7=(19/32)*Vref; 8=(20/32)*Vref; 9=(21/32)*Vref; 10=(23/32)*Vref; 11=Selects VICM (Input Common Mode) applied to DSM to be available at Ref_out DFT point; 12=Selects Vb0 (2nd and 3rd integrator Opamp Bias Voltage) inside the DSM to Ref_out DFT point; 13=Selects VRCM (Half of applied Reference) inside the DSM to Ref_out DFT point; 14=Selects vbias0_int, an internal bias point from inside the DSM to Ref_out DFT point; 15=Not a valid selection
0x40005899 ADC_DelSig_1_DSM_TST1 — Delta Sigma Modulator Test Register 1
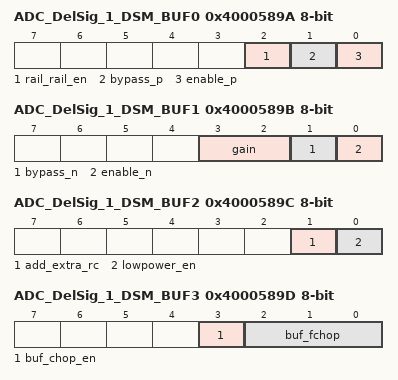
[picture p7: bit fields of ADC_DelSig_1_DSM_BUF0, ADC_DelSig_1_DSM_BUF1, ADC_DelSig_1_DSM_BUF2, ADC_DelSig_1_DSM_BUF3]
0x4000589A ADC_DelSig_1_DSM_BUF0 — Delta Sigma Modulator Buffer Register 0
  [2] rail_rail_en — Selects Rail-to-Rail Mode.
    0=RAIL_RAIL_EN_DISABLE (Level shifted mode); 1=RAIL_RAIL_EN_ENABLE (Rail-to-Rail mode)
  [1] bypass_p — Remove positive half of the buffer from signal path.
    0=The buffer in the positive half remains on the signal path (Refer Fig 33-2); 1=bypass the buffer on the positive half of the signal path (Refer Fig 33-2)
  [0] enable_p — Buffer Positive Half Enable.
    0=power down buffer in positive half; 1=enable positive half of buffer
0x4000589B ADC_DelSig_1_DSM_BUF1 — Delta Sigma Modulator Buffer Register 1
  [3:2] gain — Gain settings of 1,2,4,8 are supported.
    0=GAIN_1X (1x); 1=GAIN_2X (2x); 2=GAIN_4X (4x); 3=GAIN_8X (8x)
  [1] bypass_n — Remove negative half of the buffer from signal path.
    0=The buffer in the negative half remains on the signal path (Refer Fig 33-2); 1=bypass the buffer on the negative half of the signal path (Refer Fig 33-2)
  [0] enable_n — Buffer Negative Half Enable.
    0=power down buffer in negative half; 1=enable negat half of buffer
0x4000589C ADC_DelSig_1_DSM_BUF2 — Delta Sigma Modulator Buffer Register 2
  [1] add_extra_rc — If enabled an additional RC is included at the output of the buffer differentially, to lower noise at the expense of settling else normal settling. See s8hizbuf BROS for more information.
  [0] lowpower_en — Enables the lower power mode of operation. The normal power mode implies 600uA typical current consumption per opamp in the buffer. See s8hizbuf BROS for more information.
    0=LOWPOWER_EN_NORMAL (Input buffer operated in normal power mode); 1=LOWPOWER_EN_LOW (Input buffer operated in low (1/4th of normal power) power mode)
0x4000589D ADC_DelSig_1_DSM_BUF3 — Delta Sigma Modulator Buffer Register 3
  [3] buf_chop_en — Enable/ Disable Chopping of the input buffer (TYPE A or B as selected in DSM_BUF0 register).
    0=Disable Chopping of the input buffer; 1=Enable Chopping of the input buffer
  [2:0] buf_fchop — Input Buffer Chopping frequency control.
    0=chopping frequency is fs/2; 1=chopping frequency is fs/4; 2=chopping frequency is fs/8; 3=chopping frequency is fs/16; 4=chopping frequency is fs/32; 5=chopping frequency is fs/64; 6=chopping frequency is fs/128; 7=chopping frequency is fs/256
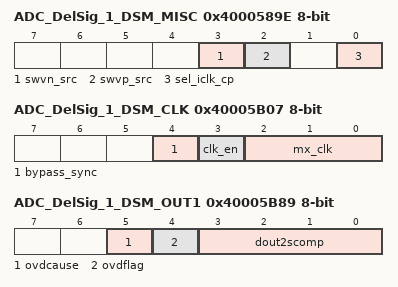
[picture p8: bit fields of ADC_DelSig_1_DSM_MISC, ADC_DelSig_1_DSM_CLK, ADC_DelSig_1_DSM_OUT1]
0x4000589E ADC_DelSig_1_DSM_MISC — Delta Sigma Modulator Miscallaneous Register
  [3] swvn_src — negative input routing control source.
    0=DSM_SWVN_SRC_REG (ANAIF DSM routing registers); 1=DSM_SWVN_SRC_UDB (UDB)
  [2] swvp_src — positive input routing control source.
    0=DSM_SWVP_SRC_REG (ANAIF DSM routing registers); 1=DSM_SWVP_SRC_UDB (UDB)
  [0] sel_iclk_cp — Select Charge Pump Internal Clock.
    0=SEL_ICLK_CP_EXTERNAL (External (DSI) Charge Pump Clock selected); 1=SEL_ICLK_CP_INTERNAL (Internal Charge Pump Clock selected)
0x40005B07 ADC_DelSig_1_DSM_CLK — Delta Sigma Modulator Clock Selection Register
  [4] bypass_sync — Bypass Synchronization
    0=Synchronization not bypassed (Synchronization enabled); 1=Synchronization bypassed (Synchronization disabled)
  [3] clk_en — Clock gating control
    0=disable clock; 1=enable clock
  [2:0] mx_clk — Clock Selection
    {v}=Select clk_a{v} and clk_a{v}_dig (v=0..3); 4=Select UDB generated clock
0x40005B88 ADC_DelSig_1_DSM_OUT0 — Delta Sigma Modulator Output Register 0
  [7:0] dout — DSM output.
0x40005B89 ADC_DelSig_1_DSM_OUT1 — Delta Sigma Modulator Output Register 1
  [5] ovdcause — Overload Cause
    0=0s overload; 1=1s overload
  [4] ovdflag — Overload detected
  [3:0] dout2scomp — DSM Output Register 1
    0=DSM_DOUT2SCOMP_0 (NA (qlev=00); 0 (qlev=01); 0 (qlev=10)); 1=DSM_DOUT2SCOMP_1 (+1 (qlev=00); +1 (qlev=01); +1 (qlev=10)); 2=DSM_DOUT2SCOMP_2 (NA (qlev=00); NA (qlev=01); +2 (qlev=10)); 3=DSM_DOUT2SCOMP_3 (NA (qlev=00); NA (qlev=01); +3 (qlev=10)); 4=DSM_DOUT2SCOMP_4 (NA (qlev=00); NA (qlev=01); +4 (qlev=10)); {v}=DSM_DOUT2SCOMP_{v} (NA (qlev=00); NA (qlev=01); NA (qlev=10)) (v=5..11); 12=DSM_DOUT2SCOMP_12 (NA (qlev=00); NA (qlev=01); -4 (qlev=10)); 13=DSM_DOUT2SCOMP_13 (NA (qlev=00); NA (qlev=01); -3 (qlev=10)); 14=DSM_DOUT2SCOMP_14 (NA (qlev=00); NA (qlev=01); -2 (qlev=10)); 15=DSM_DOUT2SCOMP_15 (-1 (qlev=00); -1 (qlev=01); -1 (qlev=10))

## HF_DAC_1_VDAC8
Base 0x00000000
0x400043A8 VDAC8_PM_ACT_CFG — Active Power Mode Configuration Register 8
  [4:0] en_dac — Enable DAC block(s). Populated subsystems are counted from the LSB
0x400043B8 VDAC8_PM_STBY_CFG — Standby Power Mode Configuration Register 8
  fields as VDAC8_PM_ACT_CFG
0x4000460A VDAC8_TR
  [7:0] tr — 8 Calibration bits
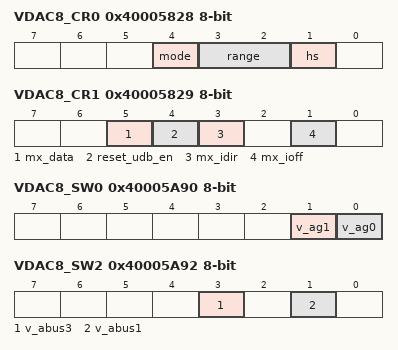
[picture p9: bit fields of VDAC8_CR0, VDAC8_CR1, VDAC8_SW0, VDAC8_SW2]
0x40005828 VDAC8_CR0 — DAC Block Control Register 0
  [4] mode ro — Mode Bit
    0=DAC_MODE_V (voltage DAC); 1=DAC_MODE_I (current DAC)
  [3:2] range — Ranges for mode=0 (VDAC) and mode=1 (IDAC)
    0=DAC_RANGE_0 (x0=0V to 4*vref (1.024V); 0 to 31.875uA); 1=DAC_RANGE_1 (x1=0V to 16*vref (4.096V); 0 to 255uA); 2=DAC_RANGE_2 (x0=0V to 4*vref (1.024V); 0 to 2.040mA); 3=DAC_RANGE_3 (x1=0V to 16*vref (4.096V); not used)
  [1] hs — High Speed Bit
    0=DAC_HS_LOWPOWER (regular (low power)); 1=DAC_HS_HIGHSPEED (high speed (higher power))
0x40005829 VDAC8_CR1 — DAC Block Control Register 1
  [5] mx_data — Select DATA source
    0=MX_DATA_REG (Select register source (DACxn_D)); 1=MX_DATA_UDB (Select UDB source)
  [4] reset_udb_en — DAC reset enable
    0=RESET_UDB_EN_DISABLE (Disable DAC Reset Source from UDB (System reset always resets)); 1=RESET_UDB_EN_ENABLE (Enable DAC Reset Source from UDB)
  [3] mx_idir — Mux selection for DAC current direction control
    0=MX_IDIR_REG (Register source idirbit selected); 1=MX_IDIR_UDB (UDB ictrl selected)
  [1] mx_ioff — Mux selection for DAC current off control
    0=MX_IOFF_REG (Register source ioffbit selected); 1=MX_IOFF_UDB (UDB ictrl selected)
0x40005A90 VDAC8_SW0 — DAC Analog Routing Register 0
  [1] v_ag1 — Connect voltage output to analog global of same side
    0=AG_NC (not connected); 1=AG_CONNECTED (Connect to Analog Global)
  [0] v_ag0 — Connect voltage output to analog global of same side
    values as v_ag1
0x40005A92 VDAC8_SW2 — DAC Analog Routing Register 2
  [3] v_abus3 — Connect voltage output to analog (local) bus of the same side
    0=ABUS_NC (not connected); 1=ABUS_CONNECTED (Connect to Analog (local) Bus)
  [1] v_abus1 — Connect voltage output to analog (local) bus of the same side
    values as v_abus3
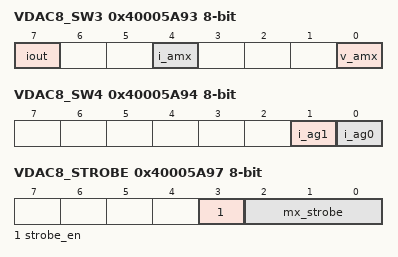
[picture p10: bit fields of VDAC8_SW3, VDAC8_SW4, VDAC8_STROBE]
0x40005A93 VDAC8_SW3 — DAC Analog Routing Register 3
  [7] iout — Connect current output to pad
    0=IOUT_NC (not connected); 1=IOUT_CONNECT (Connect to pad)
  [4] i_amx — Connect current output to Analog Mux Bus
    0=AMX_NC (not connected); 1=AMX_CONNECTED (Connect to AMUXBUS)
  [0] v_amx — Connect voltage output to Analog Mux Bus
    values as i_amx
0x40005A94 VDAC8_SW4 — DAC Analog Routing Register 4
  [1] i_ag1 — Connect current output to analog global of same side
    values as VDAC8_SW0.v_ag1
  [0] i_ag0 — Connect current output to analog global of same side
    values as VDAC8_SW0.v_ag1
0x40005A97 VDAC8_STROBE — DAC Strobe Register
  [3] strobe_en — Strobe gating control (See mx_strobe==3'h0)
    0=disable strobe; 1=enable strobe
  [2:0] mx_strobe — Strobe source selection
    0=MX_STROBE_BUSWRITE (Select bus write strobe source (Enable gater regardless of strobe_en setting)); 1=MX_STROBE_UDB_SRC (Select UDB strobe source); 2=MX_STROBE_NC_2 (NC); 3=MX_STROBE_NC_3 (NC); {v}=MX_STROBE_CLK_A{v-4}_DIG (Select clk_a{v-4}_dig) (v=4..7)
0x40005B82 VDAC8_DATA — DAC Data Register
  [7:0] data — 8 DAC Data bits
